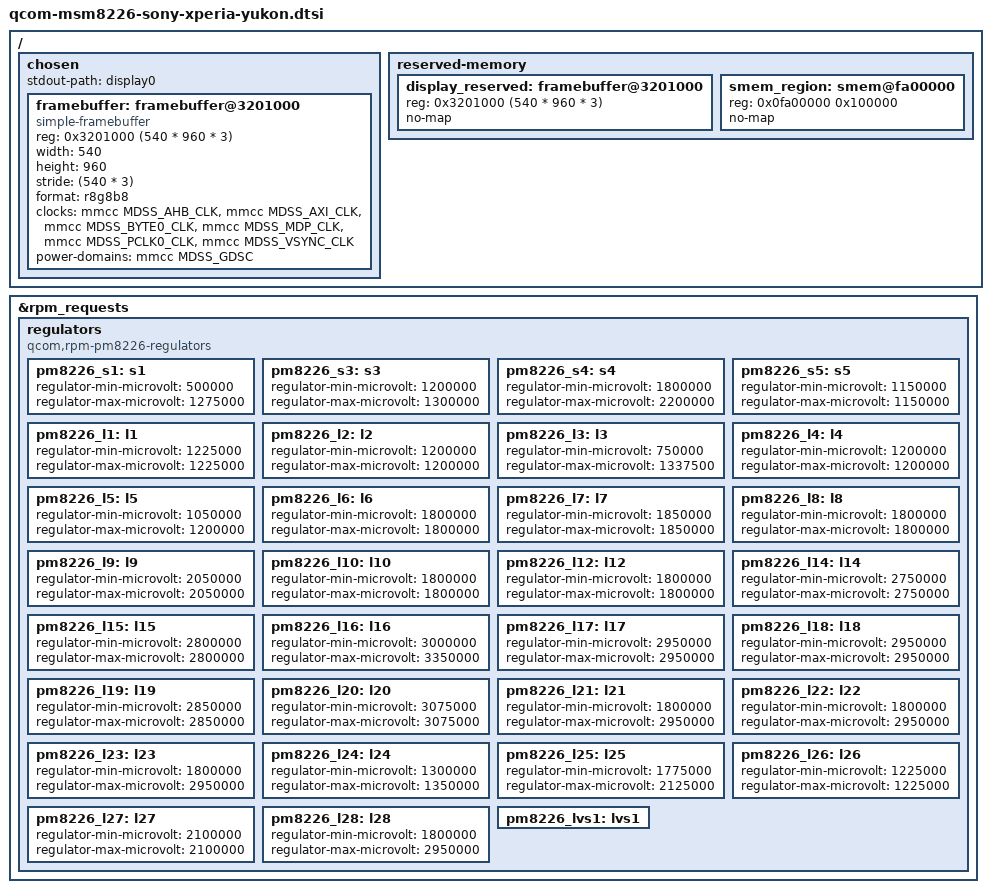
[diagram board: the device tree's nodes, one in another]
// SPDX-License-Identifier: BSD-3-Clause
/*
 * Copyright (c) 2025, Giovanni Ricca <giovanniricca@proton.me>
 */

/*
 * The .dts should first include qcom-msm8226.dtsi or msm8926.dtsi depending on
 * the SoC on the given device.
 */

#include "pm8226.dtsi"

/delete-node/ &smem_region;

/ {
	chosen {
		#address-cells = <1>;
		#size-cells = <1>;
		ranges;

		stdout-path = "display0";

		framebuffer: framebuffer@3201000 {
			compatible = "simple-framebuffer";
			reg = <0x3201000 (540 * 960 * 3)>;
			width = <540>;
			height = <960>;
			stride = <(540 * 3)>;
			format = "r8g8b8";

			clocks = <&mmcc MDSS_AHB_CLK>,
				 <&mmcc MDSS_AXI_CLK>,
				 <&mmcc MDSS_BYTE0_CLK>,
				 <&mmcc MDSS_MDP_CLK>,
				 <&mmcc MDSS_PCLK0_CLK>,
				 <&mmcc MDSS_VSYNC_CLK>;
			power-domains = <&mmcc MDSS_GDSC>;
		};
	};

	reserved-memory {
		#address-cells = <1>;
		#size-cells = <1>;
		ranges;

		display_reserved: framebuffer@3201000 {
			reg = <0x3201000 (540 * 960 * 3)>;
			no-map;
		};

		smem_region: smem@fa00000 {
			reg = <0x0fa00000 0x100000>;
			no-map;
		};
	};
};

&rpm_requests {
	regulators {
		compatible = "qcom,rpm-pm8226-regulators";

		pm8226_s1: s1 {
			regulator-min-microvolt = <500000>;
			regulator-max-microvolt = <1275000>;
		};

		pm8226_s3: s3 {
			regulator-min-microvolt = <1200000>;
			regulator-max-microvolt = <1300000>;
		};

		pm8226_s4: s4 {
			regulator-min-microvolt = <1800000>;
			regulator-max-microvolt = <2200000>;
		};

		pm8226_s5: s5 {
			regulator-min-microvolt = <1150000>;
			regulator-max-microvolt = <1150000>;
		};

		pm8226_l1: l1 {
			regulator-min-microvolt = <1225000>;
			regulator-max-microvolt = <1225000>;
		};

		pm8226_l2: l2 {
			regulator-min-microvolt = <1200000>;
			regulator-max-microvolt = <1200000>;
		};

		pm8226_l3: l3 {
			regulator-min-microvolt = <750000>;
			regulator-max-microvolt = <1337500>;
		};

		pm8226_l4: l4 {
			regulator-min-microvolt = <1200000>;
			regulator-max-microvolt = <1200000>;
		};

		pm8226_l5: l5 {
			regulator-min-microvolt = <1050000>;
			regulator-max-microvolt = <1200000>;
		};

		pm8226_l6: l6 {
			regulator-min-microvolt = <1800000>;
			regulator-max-microvolt = <1800000>;
		};

		pm8226_l7: l7 {
			regulator-min-microvolt = <1850000>;
			regulator-max-microvolt = <1850000>;
		};

		pm8226_l8: l8 {
			regulator-min-microvolt = <1800000>;
			regulator-max-microvolt = <1800000>;
		};

		pm8226_l9: l9 {
			regulator-min-microvolt = <2050000>;
			regulator-max-microvolt = <2050000>;
		};

		pm8226_l10: l10 {
			regulator-min-microvolt = <1800000>;
			regulator-max-microvolt = <1800000>;
		};

		pm8226_l12: l12 {
			regulator-min-microvolt = <1800000>;
			regulator-max-microvolt = <1800000>;
		};

		pm8226_l14: l14 {
			regulator-min-microvolt = <2750000>;
			regulator-max-microvolt = <2750000>;
		};

		pm8226_l15: l15 {
			regulator-min-microvolt = <2800000>;
			regulator-max-microvolt = <2800000>;
		};

		pm8226_l16: l16 {
			regulator-min-microvolt = <3000000>;
			regulator-max-microvolt = <3350000>;
		};

		pm8226_l17: l17 {
			regulator-min-microvolt = <2950000>;
			regulator-max-microvolt = <2950000>;
		};

		pm8226_l18: l18 {
			regulator-min-microvolt = <2950000>;
			regulator-max-microvolt = <2950000>;
		};

		pm8226_l19: l19 {
			regulator-min-microvolt = <2850000>;
			regulator-max-microvolt = <2850000>;
		};

		pm8226_l20: l20 {
			regulator-min-microvolt = <3075000>;
			regulator-max-microvolt = <3075000>;
		};

		pm8226_l21: l21 {
			regulator-min-microvolt = <1800000>;
			regulator-max-microvolt = <2950000>;
		};

		pm8226_l22: l22 {
			regulator-min-microvolt = <1800000>;
			regulator-max-microvolt = <2950000>;
		};

		pm8226_l23: l23 {
			regulator-min-microvolt = <1800000>;
			regulator-max-microvolt = <2950000>;
		};

		pm8226_l24: l24 {
			regulator-min-microvolt = <1300000>;
			regulator-max-microvolt = <1350000>;
		};

		pm8226_l25: l25 {
			regulator-min-microvolt = <1775000>;
			regulator-max-microvolt = <2125000>;
		};

		pm8226_l26: l26 {
			regulator-min-microvolt = <1225000>;
			regulator-max-microvolt = <1225000>;
		};

		pm8226_l27: l27 {
			regulator-min-microvolt = <2100000>;
			regulator-max-microvolt = <2100000>;
		};

		pm8226_l28: l28 {
			regulator-min-microvolt = <1800000>;
			regulator-max-microvolt = <2950000>;
		};

		pm8226_lvs1: lvs1 {};
	};
};
